AUTOSAR XML (schema 4-3-0)
standard types defined: boolean, sint16, sint8, uint16, uint8, boolean_CompuMethod, boolean_DataConstr, sint16_DataConstr, sint8_DataConstr, uint16_DataConstr, uint8_DataConstr, sint32
package /ASP_DataTypes
  40 x impl type:
    accPedalPosition: category=VALUE, base-type=BaseTypes/uint8
    accPedalPositionQual: category=VALUE, base-type=BaseTypes/uint8, compu {0=Cx0_Unsafe, 1=Cx1_Safe, 2=Cx2_SNA; unit Enum}
    AEB_Input: category=STRUCTURE
      4 x element, all with category=TYPE_REFERENCE:
        collAvoidSnvtySetting: range raw 0..3, implementation-data-type=collAvoidSnvtySetting
        driverAEBOverrideQual: range raw 0..3, implementation-data-type=driverAEBOverrideQual
        collAvoidSnvtySettingQual: range raw 0..3, implementation-data-type=collAvoidSnvtySettingQual
        driverAEBOverride: implementation-data-type=driverAEBOverride
    brakePedalPressed: category=VALUE, base-type=BaseTypes/boolean, compu {0=Cx0_No, 1=Cx1_Yes; unit Enum}
    brakePedalPressedQual: category=VALUE, base-type=BaseTypes/uint8, compu {0=Cx0_Unsafe, 1=Cx1_Safe, 2=Cx2_SNA; unit Enum}
    brakeTorque: category=VALUE, base-type=BaseTypes/uint16
    collAvoidSnvtySetting: category=VALUE, base-type=BaseTypes/uint8, compu {0=Cx0_NotInUse, 1=Cx1_LoSnvty, 2=Cx2_NormSnvty, 3=Cx3_HiSnvty; unit Enum}
    collAvoidSnvtySettingQual: category=VALUE, base-type=BaseTypes/uint8, compu {0=Cx0_Unsafe, 1=Cx1_Safe, 2=Cx2_SNA; unit Enum}
    Common_Zenuity_Input: category=STRUCTURE
      7 x element, all with category=TYPE_REFERENCE:
        brakePedalPressed: implementation-data-type=brakePedalPressed
        steeringWhlAngle: range raw -16384..16383, implementation-data-type=steeringWhlAngle
        accPedalPositionQual: range raw 0..3, implementation-data-type=accPedalPositionQual
        steeringWhlAngleSpeed: range raw -65536..65535, implementation-data-type=steeringWhlAngleSpeed
        accPedalPosition: range raw 0..100, implementation-data-type=accPedalPosition
        driverBrakeTorque: range raw 0..20000, implementation-data-type=driverBrakeTorque
        brakePedalPressedQual: range raw 0..3, implementation-data-type=brakePedalPressedQual
    driverAEBOverride: category=VALUE, base-type=BaseTypes/boolean, compu {0=Cx0_No, 1=Cx1_Yes; unit Enum}
    driverAEBOverrideQual: category=VALUE, base-type=BaseTypes/uint8, compu {0=Cx0_Unsafe, 1=Cx1_Safe, 2=Cx2_SNA; unit Enum}
    driverBrakeTorque: category=VALUE, base-type=BaseTypes/uint16
    dynamicWheelRadiusFront: category=VALUE, base-type=BaseTypes/uint16
    dynamicWheelRadiusRear: category=VALUE, base-type=BaseTypes/uint16
    EgoMotion: category=STRUCTURE
      20 x element, all with category=TYPE_REFERENCE:
        dynamicWheelRadiusRear: range raw 0..4095, implementation-data-type=dynamicWheelRadiusRear
        lateralAccelerationQual: range raw 0..3, implementation-data-type=lateralAccelerationQual
        lateralAcceleration: range raw -2048..2047, implementation-data-type=lateralAcceleration
        longitudinalSpeedQual: range raw 0..3, implementation-data-type=longitudinalSpeedQual
        wheelSpeedFrontRight: range raw -8192..8191, implementation-data-type=wheelSpeedFrontRight
        dynamicWheelRadiusFront: range raw 0..4095, implementation-data-type=dynamicWheelRadiusFront
        wheelSpeedQual: range raw 0..3, implementation-data-type=wheelSpeedQual
        wheelSpeedFrontLeft: range raw -8192..8191, implementation-data-type=wheelSpeedFrontLeft
        longitudinalSpeed: range raw -8192..8191, implementation-data-type=longitudinalSpeed
        rearWheelAngleQual: range raw 0..3, implementation-data-type=rearWheelAngleQual
        wheelSpeedRearRight: range raw -8192..8191, implementation-data-type=wheelSpeedRearRight
        longitudinalAccelerationQual: range raw 0..3, implementation-data-type=longitudinalAccelerationQual
        frontWheelAngle: range raw -16384..16383, implementation-data-type=frontWheelAngle
        rearWheelAngle: range raw -16384..16383, implementation-data-type=rearWheelAngle
        wheelSpeedRearLeft: range raw -8192..8191, implementation-data-type=wheelSpeedRearLeft
        frontWheelAngleQual: range raw 0..3, implementation-data-type=frontWheelAngleQual
        longitudinalAcceleration: range raw -2048..2047, implementation-data-type=longitudinalAcceleration
        yawRate: implementation-data-type=yawRate
        yawRateQual: range raw 0..3, implementation-data-type=yawRateQual
        brakeTorque: range raw 0..16383, implementation-data-type=brakeTorque
    engineState: category=VALUE, base-type=BaseTypes/uint8, compu {0=Cx0_Stop, 1=Cx1_Start, 2=Cx2_Idle_Unstable (Idle Unstable), 3=Cx3_Idle_Stable (Idle Stable), 4=Cx4_Unlimited, 5=Cx5_Limited, 6=Cx6_SNA; unit Enum}
    frontWheelAngle: category=VALUE, base-type=BaseTypes/sint16
    frontWheelAngleQual: category=VALUE, base-type=BaseTypes/uint8, compu {0=Cx0_Unavailable, 1=Cx1_Available, 2=Cx2_SNA; unit Enum}
    ignitionState: category=VALUE, base-type=BaseTypes/uint8, compu {0=Cx0_Lock, 1=Cx1_OFF, 2=Cx2_ACC, 3=Cx3_ON, 4=Cx4_Start, 5=Cx5_SNA; unit Enum}
    lateralAcceleration: category=VALUE, base-type=BaseTypes/sint16
    lateralAccelerationQual: category=VALUE, base-type=BaseTypes/uint8, compu {0=Cx0_Unavailable, 1=Cx1_Available, 2=Cx2_SNA; unit Enum}
    longitudinalAcceleration: category=VALUE, base-type=BaseTypes/sint16
    longitudinalAccelerationQual: category=VALUE, base-type=BaseTypes/uint8, compu {0=Cx0_Unavailable, 1=Cx1_Available, 2=Cx2_SNA; unit Enum}
    longitudinalSpeed: category=VALUE, base-type=BaseTypes/sint16
    longitudinalSpeedQual: category=VALUE, base-type=BaseTypes/uint8, compu {0=Cx0_Unsafe, 1=Cx1_Safe, 2=Cx2_SNA; unit Enum}
    PositionInfoType: category=STRUCTURE, sw-calibration-access=READ-ONLY, type-emitter=RTE
      element countryCode: category=VALUE, base-type=BaseTypes/uint16, sw-calibration-access=READ-ONLY, invalid-value=1023  # Current country in ISO 3166-1 numerical
    rearWheelAngle: category=VALUE, base-type=BaseTypes/sint16
    rearWheelAngleQual: category=VALUE, base-type=BaseTypes/uint8, compu {0=Cx0_Unavailable, 1=Cx1_Available, 2=Cx2_SNA; unit Enum}
    steeringWhlAngle: category=VALUE, base-type=BaseTypes/sint16
    steeringWhlAngleSpeed: category=VALUE, base-type=sint32
    suspensionType: category=VALUE, base-type=BaseTypes/uint8
    turnIndicator: category=VALUE, base-type=BaseTypes/uint8
    VehicleData: category=STRUCTURE
      4 x element, all with category=TYPE_REFERENCE, range raw 0..7:
        suspensionType: implementation-data-type=suspensionType
        ignitionState: implementation-data-type=ignitionState
        turnIndicator: implementation-data-type=turnIndicator
        engineState: implementation-data-type=engineState
    wheelSpeedFrontLeft: category=VALUE, base-type=BaseTypes/sint16
    wheelSpeedFrontRight: category=VALUE, base-type=BaseTypes/sint16
    wheelSpeedQual: category=VALUE, base-type=BaseTypes/uint8, compu {0=Cx0_Unavailable, 1=Cx1_Available, 2=Cx2_SNA; unit Enum}
    wheelSpeedRearLeft: category=VALUE, base-type=BaseTypes/sint16
    wheelSpeedRearRight: category=VALUE, base-type=BaseTypes/sint16
    yawRate: category=VALUE, base-type=BaseTypes/sint16
    yawRateQual: category=VALUE, base-type=BaseTypes/uint8, compu {0=Cx0_Unavailable, 1=Cx1_Available, 2=Cx2_SNA; unit Enum}
package /ASP_DataTypes/Units
  unit U_Enum: display-name=Enum, factor-si-to-unit=1, offset-si-to-unit=0
package /ASP_PortInterfaces
  sender receiver interface ASP_AEB_Input: invalidation-policy{data-element=AEB_Input, handle-invalid=DONT-INVALIDATE}
    data AEB_Input: type=AEB_Input
  sender receiver interface ASP_Common_Zenuity_Input: invalidation-policy{data-element=Common_Zenuity_Input, handle-invalid=DONT-INVALIDATE}
    data Common_Zenuity_Input: type=Common_Zenuity_Input
  sender receiver interface ASP_VehicleInput
    data EgoMotionElement: type=EgoMotion
    data PositionInfo: type=PositionInfoType
    data VehicleDataElement: type=VehicleData
    invalidation-policys:
      data-element=EgoMotionElement, handle-invalid=DONT-INVALIDATE
      data-element=VehicleDataElement, handle-invalid=DONT-INVALIDATE
      data-element=PositionInfo, handle-invalid=DONT-INVALIDATE
package /ComponentTypes/HkmcComponent/HkmcHbaAdap/PortInterfaces
  sender receiver interface IF_HSYS_BCM_08_200ms: invalidation-policy{data-element=DE_HSYS_BCM_08_200ms, handle-invalid=DONT-INVALIDATE}
    data DE_HSYS_BCM_08_200ms: type=HSYS_BCM_08_200ms_T
package /ComponentTypes/HkmcComponent/HkmcVehicleInputAdap
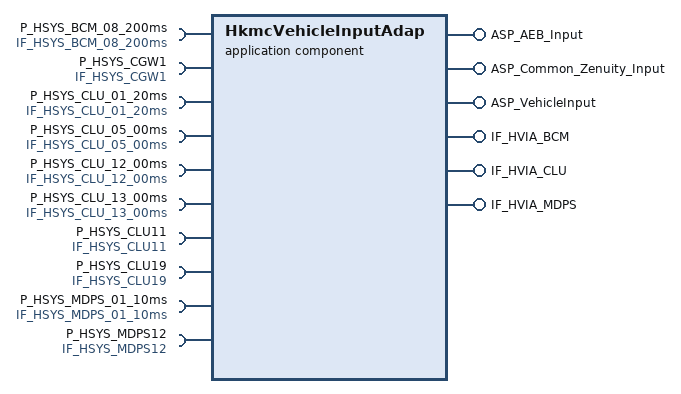
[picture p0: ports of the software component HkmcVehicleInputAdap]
  application sw component type HkmcVehicleInputAdap
    6 x provide port:
      ASP_AEB_Input: nonqueued-sender-com-spec{data-element=AEB_Input, init-value=fields=[longitudinalAccRaw:0, steeringWhlAngleSpeedQual:0, lateralAccRawQual:0, brakePedalPressed:0, vehicleMotionState:0, driverBrakeTorqueQual:0, steeringWhlAngle:0, steeringWhlAngleQual:0, accPedalPositionQual:0, collAvoidSnvtySetting:0, longitudinalAccRawQual:0, steeringWhlAngleSpeed:0, driverAEBOverrideQual:0, collAvoidSnvtySettingQual:0, driverAEBOverride:0, accPedalPosition:0, vehicleMotionStateQual:0, driverBrakeTorque:0, brakePedalPressedQual:0, lateralAccRaw:0]}, provided-interface=ASP_AEB_Input
      ASP_Common_Zenuity_Input: nonqueued-sender-com-spec{data-element=Common_Zenuity_Input, init-value=fields=[brakePedalPressed:0, steeringWhlAngle:0, accPedalPositionQual:0, steeringWhlAngleSpeed:0, accPedalPosition:0, driverBrakeTorque:0, brakePedalPressedQual:0]}, provided-interface=ASP_Common_Zenuity_Input
      ASP_VehicleInput: provided-interface=ASP_VehicleInput
        provided-com-specs:
          data-element=EgoMotionElement, init-value=fields=[dynamicWheelRadiusRear:0, lateralAccelerationQual:0, lateralAcceleration:0, longitudinalSpeedQual:0, wheelSpeedFrontRight:0, dynamicWheelRadiusFront:0, wheelSpeedQual:0, wheelSpeedFrontLeft:0, longitudinalSpeed:0, rearWheelAngleQual:0, wheelSpeedRearRight:0, longitudinalAccelerationQual:0, frontWheelAngle:0, rearWheelAngle:0, wheelSpeedRearLeft:0, frontWheelAngleQual:0, longitudinalAcceleration:0, yawRate:0, yawRateQual:0, brakeTorque:0]
          data-element=PositionInfo, init-value=fields=countryCode:0
          data-element=VehicleDataElement, init-value=fields=[suspensionType:0, ignitionState:0, turnIndicator:0, engineState:0]
      IF_HVIA_BCM: nonqueued-sender-com-spec{data-element=HVIA_BCM, init-value=fields=HkmcVehInput_HBA_ControlMode:0}, provided-interface=IF_HVIA_BCM
      IF_HVIA_CLU: nonqueued-sender-com-spec{data-element=DE_HVIA_CLU, init-value=fields=[HkmcVehicleInput_SpdUnitTyp:0, HkmcVehicleInput_Fca1stWrngSetReq:0, HkmcVehicleInput_AdasFCASetReq:0, HkmcVehicleInput_LkaModSetReq:0, HkmcVehInput_HBA_NValueSet:0]}, provided-interface=IF_HVIA_CLU
      IF_HVIA_MDPS: nonqueued-sender-com-spec{data-element=DE_HVIA_MDPS, init-value=fields=HkmcVehicleInput_LkaToiUnblSta:0}, provided-interface=IF_HVIA_MDPS
    10 x require port:
      P_HSYS_BCM_08_200ms: nonqueued-receiver-com-spec{data-element=DE_HSYS_BCM_08_200ms, filter=data-filter-type=ALWAYS}, required-interface=IF_HSYS_BCM_08_200ms
      P_HSYS_CGW1: nonqueued-receiver-com-spec{data-element=DE_HSYS_CGW1, filter=data-filter-type=ALWAYS}, required-interface=IF_HSYS_CGW1
      P_HSYS_CLU_01_20ms: nonqueued-receiver-com-spec{data-element=DE_HSYS_CLU_01_20ms, filter=data-filter-type=ALWAYS}, required-interface=IF_HSYS_CLU_01_20ms
      P_HSYS_CLU_05_00ms: nonqueued-receiver-com-spec{data-element=DE_HSYS_CLU_05_00ms, filter=data-filter-type=ALWAYS}, required-interface=IF_HSYS_CLU_05_00ms
      P_HSYS_CLU_12_00ms: nonqueued-receiver-com-spec{data-element=DE_HSYS_CLU_12_00ms, filter=data-filter-type=ALWAYS}, required-interface=IF_HSYS_CLU_12_00ms
      P_HSYS_CLU_13_00ms: nonqueued-receiver-com-spec{data-element=DE_HSYS_CLU_13_00ms, filter=data-filter-type=ALWAYS}, required-interface=IF_HSYS_CLU_13_00ms
      P_HSYS_CLU11: nonqueued-receiver-com-spec{data-element=DE_HSYS_CLU11, filter=data-filter-type=ALWAYS}, required-interface=IF_HSYS_CLU11
      P_HSYS_CLU19: nonqueued-receiver-com-spec{data-element=DE_HSYS_CLU19, filter=data-filter-type=ALWAYS}, required-interface=IF_HSYS_CLU19
      P_HSYS_MDPS_01_10ms: nonqueued-receiver-com-spec{data-element=DE_HSYS_MDPS_01_10ms, filter=data-filter-type=ALWAYS}, required-interface=IF_HSYS_MDPS_01_10ms
      P_HSYS_MDPS12: nonqueued-receiver-com-spec{data-element=DE_HSYS_MDPS12, filter=data-filter-type=ALWAYS}, required-interface=IF_HSYS_MDPS12
    behavior HkmcVehicleInputAdap_InternalBehavior
  swc implementation HkmcVehicleInputAdap_Implementation: behavior=HkmcVehicleInputAdap_InternalBehavior
    code-descriptors:
      code Default: artifact-descriptors=autosar-engineering-object={short-label=Default, category=SWSRC}
package /ComponentTypes/HkmcComponent/HkmcVehicleInputAdap/DataTypes
  13 x impl type, all with category=STRUCTURE, sw-calibration-access=READ-ONLY, type-emitter=RTE:
    HSYS_BCM_08_200ms_T
      element BCM_Crc8Val: implementation-data-type=uint8
      element BCM_AlvCnt8Val: implementation-data-type=uint8
      element Lamp_HbaCtrlModTyp: compu {0=Cx0_HbaCMT_HighControlMode_BCM, 1=Cx1_HbaCMT_HighControlMode_HBA, 2=Cx2_HbaCMT_Not_Used, 3=Cx3_HbaCMT_Error_Indicator}, implementation-data-type=uint8
    HSYS_CGW1_T
      30 x element, all with category=TYPE_REFERENCE, implementation-data-type=uint8:
        CF_Gway_IGNSw: compu {0=Cx0_IGNS_KeyOff, 1=Cx1_IGNS_KeyIn, 2=Cx2_IGNS_ACC, 3=Cx3_IGNS_IGN, 4=Cx4_IGNS_Start, 7=Cx7_IGNS_BCANSignalTimeOut}
        CF_Gway_RKECmd: compu {0=Cx0_RKEC_None, 1=Cx1_RKEC_Lock, 2=Cx2_RKEC_Unlock, 3=Cx3_RKEC_Panic, 4=Cx4_RKEC_PanicStop, 5=Cx5_RKEC_Trunk, 6=Cx6_RKEC_Reserved, 7=Cx7_RKEC_Reserved}
        CF_Gway_DrvDrSw: compu {0=Cx0_DrvDS_Close, 1=Cx1_DrvDS_Open, 3=Cx3_DrvDS_BCANSignalTimeOut}
        CF_Gway_DrvSeatBeltSw: compu {0=Cx0_DrvSBS_Unbelted, 1=Cx1_DrvSBS_Belted, 3=Cx3_DrvSBS_BCANSignalTimeOut}
        CF_Gway_TrunkTgSw: compu {0=Cx0_TrunkTS_TrunckClose, 1=Cx1_TrunkTS_TrunkOpen, 3=Cx3_TrunkTS_BCANSignalTimeOut}
        CF_Gway_SMKOption: compu {0=Cx0_SMKO_NonSMKOption, 1=Cx1_SMKO_SMKOption}
        CF_Gway_HoodSw: compu {0=Cx0_HoodS_HoodClose, 1=Cx1_HoodS_HoodOpen, 3=Cx3_HoodS_BCANSignalTimeOut}
        CF_Gway_TurnSigLh: compu {0=Cx0_TurnSL_Off, 1=Cx1_TurnSL_On, 3=Cx3_TurnSL_BCANSignalTimeOut}
        CF_Gway_WiperIntT: compu {0=Cx0_WiperIT_Step1, 1=Cx1_WiperIT_Step2, 2=Cx2_WiperIT_Step3, 3=Cx3_WiperIT_Step4, 4=Cx4_WiperIT_Step5}
        CF_Gway_WiperIntSw: compu {0=Cx0_WiperIS_Off, 1=Cx1_WiperIS_On}
        CF_Gway_WiperLowSw: compu {0=Cx0_WiperLS_Off, 1=Cx1_WiperLS_On}
        CF_Gway_WiperHighSw: compu {0=Cx0_WiperHS_Off, 1=Cx1_WiperHS_On}
        CF_Gway_WiperAutoSw: compu {0=Cx0_WiperAS_Off, 1=Cx1_WiperAS_On}
        CF_Gway_HeadLampLow: compu {0=Cx0_HeadLL_Off, 1=Cx1_HeadLL_On}
        CF_Gway_HeadLampHigh: compu {0=Cx0_HeadLH_Off, 1=Cx1_HeadLH_On}
        CF_Gway_HazardSw: compu {0=Cx0_HazS_Off, 1=Cx1_HazS_On, 3=Cx3_HazS_BCANSignalTimeOut}
        CF_Gway_AstDrSw: compu {0=Cx0_AstDS_Close, 1=Cx1_AstDS_Open}
        CF_Gway_LightSwState: compu {0=Cx0_LightSS_LightSwOff, 1=Cx1_LightSS_TailSwOn, 2=Cx2_LightSS_HeadLampLowSwOn, 3=Cx3_LightSS_AutoLightSWOn_or_DRL_Sw_On}
        CF_Gway_TSigRHSw: compu {0=Cx0_TSRS_Off, 1=Cx1_TSRS_On}
        CF_Gway_TSigLHSw: compu {0=Cx0_TSLS_Off, 1=Cx1_TSLS_On}
        CF_Gway_DriveTypeOption: compu {0=Cx0_DrvTO_LHD, 1=Cx1_DrvTO_RHD}
        CF_Gway_PassiveAccessLock: compu {0=Cx0_PassAL_None, 1=Cx1_PassAL_Lock, 2=Cx2_PassAL_PassiveTrunkLock}
        CF_Gway_PassiveAccessUnlock: compu {0=Cx0_PassAU_None, 1=Cx1_PassAU_UnLock, 2=Cx2_PassAU_UnlockOnlyDrvDoor, 3=Cx3_PassAU_PICKeyReminder}
        CF_Gway_PassingSW: compu {0=Cx0_PassS_SwOFF, 1=Cx1_PassS_SwOn}
        CF_Gway_HBAControlMode: compu {0=Cx0_HCM_HighControlModebyBCM, 1=Cx1_HCM_HighControlModebyHBA}
        CF_Gway_InhibitRMT: compu {0=Cx0_IRMT_GearRSwitchOff, 1=Cx1_IRMT_GearRSwitchOn, 3=Cx3_IRMT_BCANSignalTimeOut}
        CF_Gway_RainSnsOption: compu {0=Cx0_RainSO_NonRainSensorOption, 1=Cx1_RainSO_RainSensorOption}
        CF_SunRoofOpenState: compu {0=Cx0_SunROS_Close, 1=Cx1_SunROS_Open}
        CF_Gway_ParkBrakeSw: compu {0=Cx0_ParkBS_Off, 1=Cx1_ParkBS_On, 3=Cx3_ParkBS_BCANSignalTimeOut}
        CF_Gway_TurnSigRh: compu {0=Cx0_TurnSR_Off, 1=Cx1_TurnSR_On, 3=Cx3_TurnSR_BCANSignalTimeOut}
    HSYS_CLU_01_20ms_T
      7 x element, all with category=TYPE_REFERENCE:
        CLU_Crc1Val: implementation-data-type=uint16
        CLU_AlvCnt1Val: implementation-data-type=uint8
        CLU_DtntOutSta: compu {0=Cx0_DtntOS_Detent_Off, 1=Cx1_DtntOS_Detent_On, 2=Cx2_DtntOS_Not_used, 3=Cx3_DtntOS_Error_Indicator}, implementation-data-type=uint8
        CLU_SpdUnitTyp: compu {0=Cx0_SpdUT_kmperh, 1=Cx1_SpdUT_MPH, 2=Cx2_SpdUT_Not_used, 3=Cx3_SpdUT_Error_Indicator}, implementation-data-type=uint8
        CLU_SWRCLFASwSta: compu {0=Cx0_SWRCLFASS_Off, 1=Cx1_SWRCLFASS_Key_On, 2=Cx2_SWRCLFASS_Reserved, 3=Cx3_SWRCLFASS_Invalid}, implementation-data-type=uint8
        CLU_RhstaLvlSta: compu {0=Cx0_RheoL_Reserved, 1=Cx1_RheoL_Step1, 2=Cx2_RheoL_Step2, 3=Cx3_RheoL_Step3, 4=Cx4_RheoL_Step4, 5=Cx5_RheoL_Step5, 6=Cx6_RheoL_Step6, 7=Cx7_RheoL_Step7, 8=Cx8_RheoL_Step8, 9=Cx9_RheoL_Step9, 10=CxA_RheoL_Step10, 11=CxB_RheoL_Step11, 12=CxC_RheoL_Step12, 13=CxD_RheoL_Step13, 14=CxE_RheoL_Step14, 15=CxF_RheoL_Step15, 16=Cx10_RheoL_Step16, 17=Cx11_RheoL_Step17, 18=Cx12_RheoL_Step18, 19=Cx13_RheoL_Step19, 20=Cx14_RheoL_Step20, 21=Cx15_RheoL_Step21}, implementation-data-type=uint8
        CLU_DisSpdVal: implementation-data-type=uint8
    HSYS_CLU_05_00ms_T
      5 x element, all with category=TYPE_REFERENCE, implementation-data-type=uint8:
        USM_AAsstSetReq: compu {0=Cx0_AAsstSR_Default, 1=Cx1_AAsstSR_OFF, 2=Cx2_AAsstSR_Late, 3=Cx3_AAsstSR_Normal, 4=Cx4_AAsstSR_Early, 5=Cx5_AAsstSR_Reserved, 6=Cx6_AAsstSR_Reserved, 7=Cx7_AAsstSR_Invalid}
        USM_Fca1stWrngSetReq: compu {0=Cx0_USMFca1stWSR_Default, 1=Cx1_USMFca1stWSR_LDW_Mode, 2=Cx2_USMFca1stWSR_LKA_Mode, 3=Cx3_USMFca1stWSR_Reserved, 4=Cx4_USMFca1stWSR_Reserved, 5=Cx5_USMFca1stWSR_Reserved, 6=Cx6_USMFca1stWSR_Reserved, 7=Cx7_USMFca1stWSR_Invalid}
        USM_HADSetReq: compu {0=Cx0_HADSR_Default, 1=Cx1_HADSR_Function_On, 2=Cx2_HADSR_Function_Off, 3=Cx3_HADSR_Invalid}
        USM_IslwSetReq: compu {0=Cx0_IslwSR_Default, 1=Cx1_IslwSR_Disable, 2=Cx2_IslwSR_Enable, 3=Cx3_IslwSR_Invalid}
        USM_StaRst1Req: compu {0=Cx0_StaR1R_Default, 1=Cx1_StaR1R_Reset, 2=Cx2_StaR1R_Not_Used, 3=Cx3_StaR1R_Error_Indicator}
    HSYS_CLU_12_00ms_T
      14 x element, all with category=TYPE_REFERENCE:
        CLU_Crc12Val: implementation-data-type=uint16
        CLU_AlvCnt12Val: implementation-data-type=uint8
        USM_AdasUSMResetReq: compu {0=Cx0_AdasUSMRR_Default, 1=Cx1_AdasUSMRR_Reset, 2=Cx2_AdasUSMRR_Reserved, 3=Cx3_AdasUSMRR_Invalid}, implementation-data-type=uint8
        USM_AdasFCASetReq: compu {0=Cx0_AdasFCASR_Default, 1=Cx1_AdasFCASR_Off, 2=Cx2_AdasFCASR_Warning, 3=Cx3_AdasFCASR_Assist, 4=Cx4_AdasFCASR_Reserved, 5=Cx5_AdasFCASR_Reserved, 6=Cx6_AdasFCASR_Reserved, 7=Cx7_AdasFCASR_Invalid}, implementation-data-type=uint8
        USM_AdasSCCDrvModSetReq: compu {0=Cx0_AdasSCCDMSR_Default, 1=Cx1_AdasSCCDMSR_Comfort, 2=Cx2_AdasSCCDMSR_Normal, 3=Cx3_AdasSCCDMSR_Dynamic, 4=Cx4_AdasSCCDMSR_Reserved, 5=Cx5_AdasSCCDMSR_Reserved, 6=Cx6_AdasSCCDMSR_Reserved, 7=Cx7_AdasSCCDMSR_Invalid}, implementation-data-type=uint8
        USM_AdasDAWModSetReq: compu {0=Cx0_AdasDAWMSR_Default, 1=Cx1_AdasDAWMSR_Off, 2=Cx2_AdasDAWMSR_Reserved, 3=Cx3_AdasDAWMSR_Normal, 4=Cx4_AdasDAWMSR_Early, 5=Cx5_AdasDAWMSR_Reserved, 6=Cx6_AdasDAWMSR_Reserved, 7=Cx7_AdasDAWMSR_Invalid}, implementation-data-type=uint8
        USM_AdasHDASetReq: compu {0=Cx0_AdasHDASR_Default, 1=Cx1_AdasHDASR_Function_Off, 2=Cx2_AdasHDASR_Function_On, 3=Cx3_AdasHDASR_Invalid}, implementation-data-type=uint8
        USM_AdasNSCCCamSetReq: compu {0=Cx0_AdasNSCCCSR_Default, 1=Cx1_AdasNSCCCSR_Disable, 2=Cx2_AdasNSCCCSR_Enable, 3=Cx3_AdasNSCCCSR_Invalid}, implementation-data-type=uint8
        USM_AdasLFASetReq: compu {0=Cx0_AdasLFASR_Default, 1=Cx1_AdasLFASR_Function_Off, 2=Cx2_AdasLFASR_Function_On, 3=Cx3_AdasLFASR_Invalid}, implementation-data-type=uint8
        USM_AdasBCASetReq: compu {0=Cx0_AdasBCASR_Default, 1=Cx1_AdasBCASR_Off, 2=Cx2_AdasBCASR_Warning, 3=Cx3_AdasBCASR_Assist, 4=Cx4_AdasBCASR_Reserved, 5=Cx5_AdasBCASR_Reserved, 6=Cx6_AdasBCASR_Reserved, 7=Cx7_AdasBCASR_Invalid}, implementation-data-type=uint8
        USM_AdasISLWSetReq: compu {0=Cx0_AdasISLWSR_Default, 1=Cx1_AdasISLWSR_Disable, 2=Cx2_AdasISLWSR_Enable, 3=Cx3_AdasISLWSR_Invalid}, implementation-data-type=uint8
        USM_AdasWrngTimingSetReq: implementation-data-type=uint8
        USM_AdasLVDASetReq: compu {0=Cx0_AdasLVDASR_Default, 1=Cx1_AdasLVDASR_Off, 2=Cx2_AdasLVDASR_On, 3=Cx3_AdasLVDASR_Invalid}, implementation-data-type=uint8
        USM_AdasNSCCCrvSetReq: compu {0=Cx0_AdasNSCCCSR_Default, 1=Cx1_AdasNSCCCSR_Disable, 2=Cx2_AdasNSCCCSR_Enable, 3=Cx3_AdasNSCCCSR_Invalid}, implementation-data-type=uint8
    HSYS_CLU_13_00ms_T
      7 x element, all with category=TYPE_REFERENCE:
        CLU_Crc13Val: implementation-data-type=uint16
        CLU_AlvCnt13Val: implementation-data-type=uint8
        USM_AdasLkaModSetReq: compu {0=Cx0_AdasLkaMSR_Default, 1=Cx1_AdasLkaMSR_LDW_mode, 2=Cx2_AdasLkaMSR_LKA_mode, 3=Cx3_AdasLkaMSR_ACTIVE_LKA, 4=Cx4_AdasLkaMSR_LDW_ON, 5=Cx5_AdasLkaMSR_LDW_OFF, 6=Cx6_AdasLkaMSR_LDW_LKA_OFF, 7=Cx7_AdasLkaMSR_Invalid}, implementation-data-type=uint8
        USM_AdasFCAJnctnSetReq: compu {0=Cx0_AdasFCAJSR_Default, 1=Cx1_AdasFCAJSR_Off, 2=Cx2_AdasFCAJSR_On, 3=Cx3_AdasFCAJSR_Invalid}, implementation-data-type=uint8
        USM_AdasHbaSetReq: compu {0=Cx0_AdasHbaSR_Default, 1=Cx1_AdasHbaSR_Off, 2=Cx2_AdasHbaSR_On, 3=Cx3_AdasHbaSR_Invalid}, implementation-data-type=uint8
        USM_AdasSCCMLSetReq: compu {0=Cx0_AdasSCCMLSR_Default, 1=Cx1_AdasSCCMLSR_Off, 2=Cx2_AdasSCCMLSR_On, 3=Cx3_AdasSCCMLSR_Invalid}, implementation-data-type=uint8
        USM_AdasSCCMLResetReq: compu {0=Cx0_AdasSCCMLRR_Default, 1=Cx1_AdasSCCMLRR_Reset, 2=Cx2_AdasSCCMLRR_Reserved, 3=Cx3_AdasSCCMLRR_Invalid}, implementation-data-type=uint8
    HSYS_CLU11_T
      10 x element, all with category=TYPE_REFERENCE:
        CF_Clu_CruiseSwState: compu {0=Cx0_CruiseSS_IdlePosition, 1=Cx1_CruiseSS_Resume_Plus, 2=Cx2_CruiseSS_Set_Minus, 3=Cx3_CruiseSS_Time_Gap, 4=Cx4_CruiseSS_ACC_SCC_Cancel, 5=Cx5_CruiseSS_Reserved, 6=Cx6_CruiseSS_Reserved, 7=Cx7_CruiseSS_Reserved}, implementation-data-type=uint8
        CF_Clu_CruiseSwMain: compu {0=Cx0_CruiseSM_Off, 1=Cx1_CruiseSM_On}, implementation-data-type=uint8
        CF_Clu_SldMainSW: compu {0=Cx0_SldMS_Off, 1=Cx1_SldSMS_On}, implementation-data-type=uint8
        CF_Clu_ParityBit1: implementation-data-type=boolean
        CF_Clu_VanzDecimal: implementation-data-type=uint8
        CF_Clu_Vanz: implementation-data-type=uint8
        CF_Clu_SPEED_UNIT: compu {0=Cx0_SpeedU_kmperh, 1=Cx1_SpeedU_MPH}, implementation-data-type=uint8
        CF_Clu_DetentOut: compu {0=Cx0_DO_DetentOff, 1=Cx1_DO_DetentOn}, implementation-data-type=uint8
        CF_Clu_RheostatLevel: compu {0=Cx0_RheoL_Reserved, 1=Cx1_RheoL_Step1, 2=Cx2_RheoL_Step2, 3=Cx3_RheoL_Step3, 4=Cx4_RheoL_Step4, 5=Cx5_RheoL_Step5, 6=Cx6_RheoL_Step6, 7=Cx7_RheoL_Step7, 8=Cx8_RheoL_Step8, 9=Cx9_RheoL_Step9, 10=CxA_RheoL_Step10, 11=CxB_RheoL_Step11, 12=Cx12_RheoL_Step12, 13=CxD_RheoL_Step13, 14=CxE_RheoL_Step14, 15=CxF_RheoL_Step15, 16=Cx10_RheoL_Step16, 17=Cx11_RheoL_Step17, 18=Cx12_RheoL_Step18, 19=Cx13_RheoL_Step19, 20=Cx14_RheoL_Step20, 21=Cx15_RheoL_Step21}, implementation-data-type=uint8
        CF_Clu_AliveCnt1: implementation-data-type=uint8
    HSYS_CLU19_T
      10 x element, all with category=TYPE_REFERENCE, implementation-data-type=uint8:
        CF_AVN_FCANValueSet: compu {0=Cx0_FCANVS_Default, 1=Cx1_FCANVS_Off, 2=Cx2_FCANVS_Warning, 3=Cx3_FCANVS_Assist, 4=Cx4_FCANVS_Reserved, 5=Cx5_FCANVS_Reserved, 6=Cx6_FCANVS_Reserved, 7=Cx7_FCANVS_Invalid}
        CF_AVN_CluUSMReset: compu {0=Cx0_CluUSMR_Default, 1=Cx1_CluUSMR_Reset}
        CF_AVN_SCCDrvModeNValueSet: compu {0=Cx0_SCCDrvMNVS_Default, 1=Cx1_SCCDrvMNVS_Comfort, 2=Cx2_SCCDrvMNVS_Normal, 3=Cx3_SCCDrvMNVS_Dynamic, 4=Cx4_SCCDrvMNVS_Reserved, 5=Cx5_SCCDrvMNVS_Reserved, 6=Cx6_SCCDrvMNVS_Reserved, 7=Cx7_SCCDrvMNVS_Invalid}
        CF_AVN_NSCCCamNValueSet: compu {0=Cx0_NSCCCNVS_Default, 1=Cx1_NSCCCNVS_Disable, 2=Cx2_NSCCCNVS_Enable, 3=Cx3_NSCCCNVS_Invalid}
        CF_AVN_WarningTimingNValueSet: compu {0=Cx0_WarnTNVS_Default, 1=Cx1_WarnTNVS_LDW_Mode, 2=Cx2_WarnTNVS_LKA_Mode, 3=Cx3_WarnTNVS_Reserved, 4=Cx4_WarnTNVS_Reserved, 5=Cx5_WarnTNVS_Reserved, 6=Cx6_WarnTNVS_Reserved, 7=Cx7_WarnTNVS_Invalid}
        CF_AVN_LVDANValueSet: compu {0=Cx0_LVDANLVS_Default, 1=Cx1_LVDANLVS_Off, 2=Cx2_LVDANLVS_On, 3=Cx3_LVDANLVS_Invalid}
        CF_AVN_LkaModeNValueSet: compu {0=Cx0_LkaMNVS_Default, 1=Cx1_LkaMNVS_LDW_mode, 2=Cx2_LkaMNVS_LKA_mode, 3=Cx3_LkaMNVS_ACTIVE_LKA, 4=Cx4_LkaMNVS_LDW_ON, 5=Cx5_LkaMNVS_LDW_OFF, 6=Cx6_LkaMNVS_LDW_LKA_OFF, 7=Cx7_LkaMNVS_Invalid}
        CF_AVN_HBANValueSet: compu {0=Cx0_HBANVS_Default, 1=Cx1_HBANVS_HBAOff, 2=Cx2_HBANVS_HBAOn, 3=Cx3_HBANVS_Invalid}
        CF_AVN_DAWModeNValueSet_New: compu {0=Cx0_DAWMNVSN_Default, 1=Cx1_DAWMNVSN_Off, 2=Cx2_DAWMNVSN_On, 3=Cx3_DAWMNVSN_Invalid}
        CF_Clu_DawResetReq: compu {0=Cx0_DawRR_Default, 1=Cx1_DawRR_ResetReq}
    HSYS_MDPS_01_10ms_T
      13 x element, all with category=TYPE_REFERENCE:
        MDPS_Crc1Val: implementation-data-type=uint16
        MDPS_AlvCnt1Val: implementation-data-type=uint8
        MDPS_Typ: compu {0=Cx0_Typ_C_MDPS, 1=Cx1_Typ_R_MDPS_Pinion, 2=Cx2_Typ_R_MDPS_Belt, 6=Cx6_Typ_Not_Used, 7=Cx7_Typ_Error_Indicator}, implementation-data-type=uint8
        MDPS_PaModeSta: compu {0=Cx0_PMS_Reserved, 1=Cx1_PMS_Steering_still_in_initialization_phas, 2=Cx2_PMS_Steering_ready_waits_for_PA_command, 3=Cx3_PMS_Steering_set_in_standby_PA, 4=Cx4_PMS_Steering_requested_to_go_to_first_activation_step, 5=Cx5_PMS_Steering_requested_to_go_to_final_activation_step, 6=Cx6_PMS_Steering_went_to_error_internally, 7=Cx7_PMS_Steering_aborted_the_automatic_function, 15=CxE_PMS_Not_Used, 16=CxF_PMS_Error_Indicator}, implementation-data-type=uint8
        MDPS_LkaPlgInSta: compu {0=Cx0_LkaPIS_MDPS_Not_Plugged, 1=Cx1_LkaPIS_MDPS_Plugged_In, 2=Cx2_LkaPIS_Not_Used, 3=Cx3_LkaPIS_Error_Indicator}, implementation-data-type=uint8
        MDPS_LkaToiActvSta: compu {0=Cx0_LkaTAS_Deactivated, 1=Cx1_LkaTAS_Activated, 2=Cx2_LkaTAS_Not_Used, 3=Cx3_LkaTAS_Error_Indicator}, implementation-data-type=uint8
        MDPS_LkaToiUnblSta: compu {0=Cx0_LkaTUS_Available, 1=Cx1_LkaTUS_Unavailable, 2=Cx2_LkaTUS_Not_used, 3=Cx3_LkaTUS_Error_Indicator}, implementation-data-type=uint8
        MDPS_LkaToiFltSta: compu {0=Cx0_LkaTFS_No_Fault, 1=Cx1_LkaTFS_Faulty, 2=Cx2_LkaTFS_Not_used, 3=Cx3_LkaTFS_Error_Indicator}, implementation-data-type=uint8
        MDPS_LkaFailSta: compu {0=Cx0_LkaFS_Not_Fail_State, 1=Cx1_LkaFS_Fail_State, 2=Cx2_LkaFS_Not_used, 3=Cx3_LkaFS_Error_Indicator}, implementation-data-type=uint8
        MDPS_FlxStrSta: compu {0=Cx0_FlxSS_Standard_Mode, 1=Cx1_FlxSS_Sport_Mode, 2=Cx2_FlxSS_Comfort_Mode, 3=Cx3_FlxSS_Reserved, 4=Cx4_FlxSS_Reserved, 5=Cx5_FlxSS_Reserved, 6=Cx6_FlxSS_Not_Used, 7=Cx7_FlxSS_Invalid}, implementation-data-type=uint8
        MDPS_CurrModVal: compu {0=Cx0_CurrMV_Standard_Mode, 1=Cx1_CurrMV_Sport_Mode, 2=Cx2_CurrMV_Comfort_Mode, 3=Cx3_CurrMV_Reserved, 4=Cx4_CurrMV_Reserved, 5=Cx5_CurrMV_Reserved, 6=Cx6_CurrMV_Not_Used, 7=Cx7_CurrMV_Error_Indicator}, implementation-data-type=uint8
        MDPS_OutTqVal: compu {0=Cx0_OutTV_Not_Used, 1=Cx1_OutTV_Error_Indicator}, implementation-data-type=uint8
        MDPS_StrTqSnsrVal: compu {0=Cx0_StrTSV_Not_Used, 1=Cx1_StrTSV_Error_Indicator}, implementation-data-type=uint8
    HSYS_MDPS12_T
      11 x element, all with category=TYPE_REFERENCE:
        CR_Mdps_StrColTq: implementation-data-type=sint8
        CF_Mdps_Def: compu {0=Cx0_Def_Not_Defective, 1=Cx1_Def_Defective}, implementation-data-type=uint8
        CF_Mdps_ToiUnavail: compu {0=Cx0_TU_Available, 1=Cx1_TU_Unavailable}, implementation-data-type=uint8
        CF_Mdps_ToiActive: compu {0=Cx0_TA_Deactivated, 1=Cx1_TA_Activated}, implementation-data-type=uint8
        CF_Mdps_ToiFlt: compu {0=Cx0_TF_NoFault, 1=Cx1_TF_Faulty}, implementation-data-type=uint8
        CF_Mdps_FailStat: compu {0=Cx0_MdpsFS_NotFailState, 1=Cx1_MdpsFS_FailState}, implementation-data-type=uint8
        CF_Mdps_MsgCount2: implementation-data-type=uint8
        CF_Mdps_Chksum2: implementation-data-type=uint8
        CF_Mdps_SErr: compu {0=Cx0_SE_VSM1Signal_NotError, 1=Cx1_SE_VSM1Signal_Error}, implementation-data-type=uint8
        CR_Mdps_StrTq: implementation-data-type=sint8
        CR_Mdps_OutTq: implementation-data-type=sint16
    HVIA_BCM_T
      element HkmcVehInput_HBA_ControlMode: compu {0=Cx0_ContM_HighControlMode_BCM, 1=Cx1_ContM_HighControlMode_HBA, 2=Cx2_ContM_Not_Used, 3=Cx3_ContM_Error_Indicator}, implementation-data-type=uint8
    HVIA_CLU_T
      5 x element, all with category=TYPE_REFERENCE, implementation-data-type=uint8:
        HkmcVehicleInput_SpdUnitTyp: compu {0=Cx0_SpdUT_kmperh, 1=Cx1_SpdUT_MPH, 2=Cx2_SpdUT_Not_used, 3=Cx3_SpdUT_Error_Indicator}
        HkmcVehicleInput_Fca1stWrngSetReq: compu {0=Cx0_Fca1stWSR_Default, 1=Cx1_Fca1stWSR_LDW_Mode, 2=Cx2_Fca1stWSR_LKA_Mode, 3=Cx3_Fca1stWSR_Reserved, 4=Cx4_Fca1stWSR_Reserved, 5=Cx5_Fca1stWSR_Reserved, 6=Cx6_Fca1stWSR_Reserved, 7=Cx7_Fca1stWSR_Invalid}
        HkmcVehicleInput_AdasFCASetReq: compu {0=Cx0_AdasFCASR_Default, 1=Cx1_AdasFCASR_Off, 2=Cx2_AdasFCASR_Warning, 3=Cx3_AdasFCASR_Assist, 4=Cx4_AdasFCASR_Reserved, 5=Cx5_AdasFCASR_Reserved, 6=Cx6_AdasFCASR_Reserved, 7=Cx7_AdasFCASR_Invalid}
        HkmcVehicleInput_LkaModSetReq: compu {0=Cx0_LkaModSR_Default, 1=Cx1_LkaModSR_LDW_mode, 2=Cx2_LkaModSR_LKA_mode, 3=Cx3_LkaModSR_ACTIVE_LKA, 4=Cx4_LkaModSR_LDW_ON, 5=Cx5_LkaModSR_LDW_OFF, 6=Cx6_LkaModSR_LDW_LKA_OFF, 7=Cx7_LkaModSR_Invalid}
        HkmcVehInput_HBA_NValueSet: compu {0=Cx0_NVS_Default, 1=Cx1_NVS_HBA_Off, 2=Cx2_NVS_HBA_On, 3=Cx3_NVS_Invalid}
    HVIA_MDPS_T
      element HkmcVehicleInput_LkaToiUnblSta: compu {0=Cx0_LkaTUS_Available, 1=Cx1_LkaTUS_Unavailable, 2=Cx2_LkaTUS_Not_Used, 3=Cx3_LkaTUS_Error_Indicator}, implementation-data-type=uint8
package /ComponentTypes/HkmcComponent/HkmcVehicleInputAdap/PortInterfaces
  12 x sender receiver interface:
    IF_HSYS_CGW1: invalidation-policy{data-element=DE_HSYS_CGW1, handle-invalid=DONT-INVALIDATE}
      data DE_HSYS_CGW1: type=HSYS_CGW1_T
    IF_HSYS_CLU_01_20ms: invalidation-policy{data-element=DE_HSYS_CLU_01_20ms, handle-invalid=DONT-INVALIDATE}
      data DE_HSYS_CLU_01_20ms: type=HSYS_CLU_01_20ms_T
    IF_HSYS_CLU_05_00ms: invalidation-policy{data-element=DE_HSYS_CLU_05_00ms, handle-invalid=DONT-INVALIDATE}
      data DE_HSYS_CLU_05_00ms: type=HSYS_CLU_05_00ms_T
    IF_HSYS_CLU_12_00ms: invalidation-policy{data-element=DE_HSYS_CLU_12_00ms, handle-invalid=DONT-INVALIDATE}
      data DE_HSYS_CLU_12_00ms: type=HSYS_CLU_12_00ms_T
    IF_HSYS_CLU_13_00ms: invalidation-policy{data-element=DE_HSYS_CLU_13_00ms, handle-invalid=DONT-INVALIDATE}
      data DE_HSYS_CLU_13_00ms: type=HSYS_CLU_13_00ms_T
    IF_HSYS_CLU11: invalidation-policy{data-element=DE_HSYS_CLU11, handle-invalid=DONT-INVALIDATE}
      data DE_HSYS_CLU11: type=HSYS_CLU11_T
    IF_HSYS_CLU19: invalidation-policy{data-element=DE_HSYS_CLU19, handle-invalid=DONT-INVALIDATE}
      data DE_HSYS_CLU19: type=HSYS_CLU19_T
    IF_HSYS_MDPS_01_10ms: invalidation-policy{data-element=DE_HSYS_MDPS_01_10ms, handle-invalid=DONT-INVALIDATE}
      data DE_HSYS_MDPS_01_10ms: type=HSYS_MDPS_01_10ms_T
    IF_HSYS_MDPS12: invalidation-policy{data-element=DE_HSYS_MDPS12, handle-invalid=DONT-INVALIDATE}
      data DE_HSYS_MDPS12: type=HSYS_MDPS12_T
    IF_HVIA_BCM: invalidation-policy{data-element=HVIA_BCM, handle-invalid=DONT-INVALIDATE}
      data HVIA_BCM: type=HVIA_BCM_T
    IF_HVIA_CLU: invalidation-policy{data-element=DE_HVIA_CLU, handle-invalid=DONT-INVALIDATE}
      data DE_HVIA_CLU: type=HVIA_CLU_T
    IF_HVIA_MDPS: invalidation-policy{data-element=DE_HVIA_MDPS, handle-invalid=DONT-INVALIDATE}
      data DE_HVIA_MDPS: type=HVIA_MDPS_T
